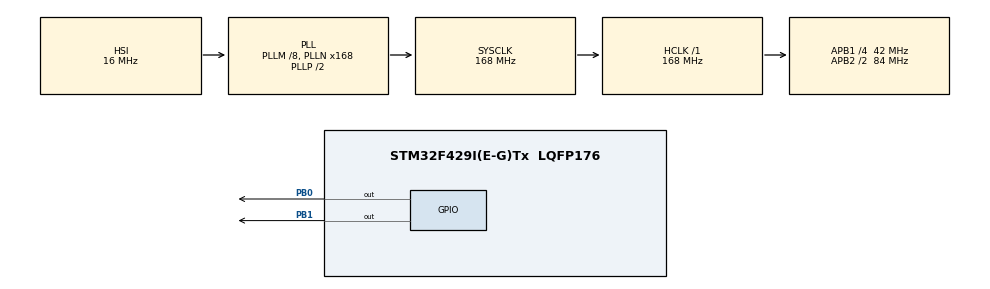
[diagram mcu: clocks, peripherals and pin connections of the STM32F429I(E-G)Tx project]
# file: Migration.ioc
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FREERTOS.Tasks01=defaultTask,0,128,StartDefaultTask,Default,NULL,Dynamic,NULL,NULL
Mcu.Family=STM32F4
Mcu.Name=STM32F429I(E-G)Tx
Mcu.Package=LQFP176
NVIC.PriorityGroup=NVIC_PRIORITYGROUP_4
NVIC.TIM1_UP_TIM10_IRQn=true\:0\:0\:false\:false\:true\:false\:false\:true
NVIC.TimeBase=TIM1_UP_TIM10_IRQn
NVIC.TimeBaseIP=TIM1
PB0.Signal=GPIO_Output
PB1.Signal=GPIO_Output
ProjectManager.HeapSize=0x200
ProjectManager.StackSize=0x400
ProjectManager.TargetToolchain=MDK-ARM V5
RCC.48MHZClocksFreq_Value=84000000
RCC.AHBFreq_Value=168000000
RCC.APB1CLKDivider=RCC_HCLK_DIV4
RCC.APB1Freq_Value=42000000
RCC.APB1TimFreq_Value=84000000
RCC.APB2CLKDivider=RCC_HCLK_DIV2
RCC.APB2Freq_Value=84000000
RCC.APB2TimFreq_Value=168000000
RCC.CortexFreq_Value=168000000
RCC.HCLKFreq_Value=168000000
RCC.HSE_VALUE=25000000
RCC.HSI_VALUE=16000000
RCC.LSE_VALUE=32768
RCC.PLLM=8
RCC.PLLN=168
RCC.SYSCLKFreq_VALUE=168000000
RCC.SYSCLKSource=RCC_SYSCLKSOURCE_PLLCLK
RCC.VCOOutputFreq_Value=336000000
VP_FREERTOS_VS_CMSIS_V1.Mode=CMSIS_V1
VP_SYS_VS_tim1.Mode=TIM1
board=custom

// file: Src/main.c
/* USER CODE BEGIN Header */
/**
  ******************************************************************************
  * @file           : main.c
  * @brief          : Main program body
  ******************************************************************************
  * @attention
  *
  * <h2><center>&copy; Copyright (c) 2019 STMicroelectronics.
  * All rights reserved.</center></h2>
  *
  * This software component is licensed by ST under Ultimate Liberty license
  * SLA0044, the "License"; You may not use this file except in compliance with
  * the License. You may obtain a copy of the License at:
  *                             www.st.com/SLA0044
  *
  ******************************************************************************
  */
/* USER CODE END Header */

#include "main.h"
#include "cmsis_os.h"

osThreadId defaultTaskHandle;
osThreadId defaultTaskHandle2;

void SystemClock_Config(void);
static void MX_GPIO_Init(void);
void StartDefaultTask(void const * argument);
void StartDefaultTask2(void const * argument);

int main(void)
{

  /* MCU Configuration--------------------------------------------------------*/

  /* Reset of all peripherals, Initializes the Flash interface and the Systick. */
  HAL_Init();

  /* Configure the system clock */
  SystemClock_Config();

  /* Initialize all configured peripherals */
  MX_GPIO_Init();

  /* Create the thread(s) */
  /* definition and creation of defaultTask */
  osThreadDef(defaultTask, StartDefaultTask, osPriorityNormal, 0, 128);
  defaultTaskHandle = osThreadCreate(osThread(defaultTask), NULL);

  /* USER CODE BEGIN RTOS_THREADS */
  /* add threads, ... */
	osThreadDef(defaultTask2, StartDefaultTask2, osPriorityNormal, 0, 128);
	defaultTaskHandle2 = osThreadCreate(osThread(defaultTask2), NULL);
  /* USER CODE END RTOS_THREADS */

  /* Start scheduler */
  osKernelStart();

  /* We should never get here as control is now taken by the scheduler */

  /* Infinite loop */
  while (1)
  {

  }
}

void SystemClock_Config(void)
{
  RCC_OscInitTypeDef RCC_OscInitStruct = {0};
  RCC_ClkInitTypeDef RCC_ClkInitStruct = {0};

  /** Configure the main internal regulator output voltage
  */
  __HAL_RCC_PWR_CLK_ENABLE();
  __HAL_PWR_VOLTAGESCALING_CONFIG(PWR_REGULATOR_VOLTAGE_SCALE1);
  /** Initializes the CPU, AHB and APB busses clocks
  */
  RCC_OscInitStruct.OscillatorType = RCC_OSCILLATORTYPE_HSI;
  RCC_OscInitStruct.HSIState = RCC_HSI_ON;
  RCC_OscInitStruct.HSICalibrationValue = RCC_HSICALIBRATION_DEFAULT;
  RCC_OscInitStruct.PLL.PLLState = RCC_PLL_ON;
  RCC_OscInitStruct.PLL.PLLSource = RCC_PLLSOURCE_HSI;
  RCC_OscInitStruct.PLL.PLLM = 8;
  RCC_OscInitStruct.PLL.PLLN = 168;
  RCC_OscInitStruct.PLL.PLLP = RCC_PLLP_DIV2;
  RCC_OscInitStruct.PLL.PLLQ = 4;
  if (HAL_RCC_OscConfig(&RCC_OscInitStruct) != HAL_OK)
  {
    Error_Handler();
  }
  /** Initializes the CPU, AHB and APB busses clocks
  */
  RCC_ClkInitStruct.ClockType = RCC_CLOCKTYPE_HCLK|RCC_CLOCKTYPE_SYSCLK
                              |RCC_CLOCKTYPE_PCLK1|RCC_CLOCKTYPE_PCLK2;
  RCC_ClkInitStruct.SYSCLKSource = RCC_SYSCLKSOURCE_PLLCLK;
  RCC_ClkInitStruct.AHBCLKDivider = RCC_SYSCLK_DIV1;
  RCC_ClkInitStruct.APB1CLKDivider = RCC_HCLK_DIV4;
  RCC_ClkInitStruct.APB2CLKDivider = RCC_HCLK_DIV2;

  if (HAL_RCC_ClockConfig(&RCC_ClkInitStruct, FLASH_LATENCY_5) != HAL_OK)
  {
    Error_Handler();
  }
}

static void MX_GPIO_Init(void)
{
  GPIO_InitTypeDef GPIO_InitStruct = {0};

  /* GPIO Ports Clock Enable */
  __HAL_RCC_GPIOB_CLK_ENABLE();

  /*Configure GPIO pin Output Level */
  HAL_GPIO_WritePin(GPIOB, GPIO_PIN_0|GPIO_PIN_1, GPIO_PIN_RESET);

  /*Configure GPIO pins : PB0 PB1 */
  GPIO_InitStruct.Pin = GPIO_PIN_0|GPIO_PIN_1;
  GPIO_InitStruct.Mode = GPIO_MODE_OUTPUT_PP;
  GPIO_InitStruct.Pull = GPIO_NOPULL;
  GPIO_InitStruct.Speed = GPIO_SPEED_FREQ_LOW;
  HAL_GPIO_Init(GPIOB, &GPIO_InitStruct);

}

/* USER CODE BEGIN 4 */
void StartDefaultTask2(void const * argument)
{

  /* Infinite loop */
  for(;;)
  {
    osDelay(1);
		HAL_GPIO_TogglePin(GPIOB,GPIO_PIN_1);
		HAL_Delay(250);
  }
}
/* USER CODE END 4 */

void StartDefaultTask(void const * argument)
{

  /* USER CODE BEGIN 5 */
  /* Infinite loop */
  for(;;)
  {
    osDelay(1);
		HAL_GPIO_TogglePin(GPIOB,GPIO_PIN_0);
		HAL_Delay(1000);
  }
  /* USER CODE END 5 */
}

void HAL_TIM_PeriodElapsedCallback(TIM_HandleTypeDef *htim)
{
  if (htim->Instance == TIM1) {
    HAL_IncTick();
  }
}

void Error_Handler(void)
{
}

#ifdef  USE_FULL_ASSERT
/**
  * @brief  Reports the name of the source file and the source line number
  *         where the assert_param error has occurred.
  * @param  file: pointer to the source file name
  * @param  line: assert_param error line source number
  * @retval None
  */
void assert_failed(uint8_t *file, uint32_t line)
{
  /* USER CODE BEGIN 6 */
  /* Infinite loop */
  for(;;)
  {
    osDelay(1);
		HAL_GPIO_TogglePin(GPIOB,GPIO_PIN_1);
		HAL_Delay(250);
  }
  /* USER CODE END 6 */
}
#endif /* USE_FULL_ASSERT */

/************************ (C) COPYRIGHT STMicroelectronics *****END OF FILE****/
